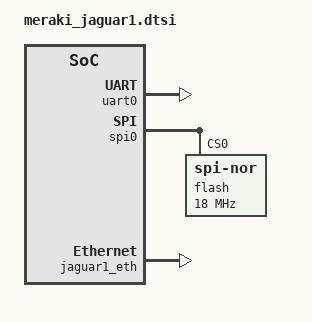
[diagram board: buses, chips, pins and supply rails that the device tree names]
// SPDX-License-Identifier: (GPL-2.0+ OR MIT)

#include "mscc,jaguar1.dtsi"

/ {
	aliases {
		serial0 = &uart0;
		spi0 = &spi0;
		ethernet0 = &jaguar1_eth;
	};

	chosen {
		stdout-path = "serial0:115200n8";
	};
};

&uart0 {
	status = "okay";
};

&spi0 {
	status = "okay";

	flash@0 {
		compatible = "jedec,spi-nor";
		reg = <0>;
		spi-max-frequency = <18000000>;
		spi-cs-high;
	};
};

&jaguar1_eth {
	status = "okay";
};
